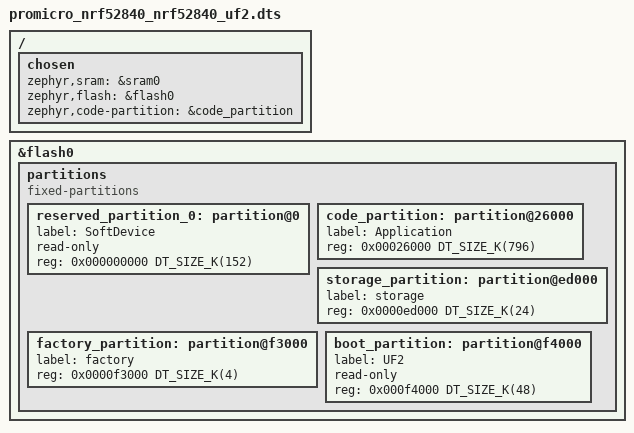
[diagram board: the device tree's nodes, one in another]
/*
 * Copyright (c) 2024 MASSDRIVER EI (massdriver.space)
 *
 * SPDX-License-Identifier: Apache-2.0
 *
 * Pro Micro / SuperMini nRF52840 with the Adafruit nRF52 UF2 bootloader.
 *
 * NCS v2.9.3's Zephyr does not ship nordic/nrf52840_partition_uf2_sdv6.dtsi, so
 * the standard Adafruit "SoftDevice v6" UF2 flash layout is inlined here:
 *   - 0x00000000..0x00026000 (152K) reserved (SoftDevice region the UF2
 *     bootloader expects; unused by Zephyr but the app MUST start at 0x26000).
 *   - 0x00026000 (796K) Application   -> code_partition (UF2 flashes here).
 *   - 0x000ed000 (24K)  storage       -> Matter settings (NVS).
 *   - 0x000f3000 (4K)   factory       -> per-device provisioning blob.
 *   - 0x000f4000 (48K)  UF2 bootloader (read-only).
 */

/dts-v1/;
#include "promicro_nrf52840_nrf52840_common.dts"

/ {
	chosen {
		zephyr,sram = &sram0;
		zephyr,flash = &flash0;
		zephyr,code-partition = &code_partition;
	};
};

&flash0 {
	partitions {
		compatible = "fixed-partitions";
		#address-cells = <1>;
		#size-cells = <1>;

		reserved_partition_0: partition@0 {
			label = "SoftDevice";
			read-only;
			reg = <0x000000000 DT_SIZE_K(152)>;
		};

		code_partition: partition@26000 {
			label = "Application";
			reg = <0x00026000 DT_SIZE_K(796)>;
		};

		/*
		 * 0x000ed000..0x000f3000 (24K) — application settings/NVS store
		 * (Matter commissioning data, fabrics, ...).
		 */
		storage_partition: partition@ed000 {
			label = "storage";
			reg = <0x0000ed000 DT_SIZE_K(24)>;
		};

		/*
		 * 0x000f3000..0x000f4000 (one 4K page) — per-device provisioning
		 * blob {discriminator, passcode, serial}. The browser provisioning
		 * tool writes it as a SEPARATE UF2 targeting this fixed offset, so a
		 * unit can be (re)provisioned without touching the app. Blank (0xFF)
		 * -> firmware falls back to the compiled-in test creds.
		 */
		factory_partition: partition@f3000 {
			label = "factory";
			reg = <0x0000f3000 DT_SIZE_K(4)>;
		};

		boot_partition: partition@f4000 {
			label = "UF2";
			read-only;
			reg = <0x000f4000 DT_SIZE_K(48)>;
		};
	};
};
